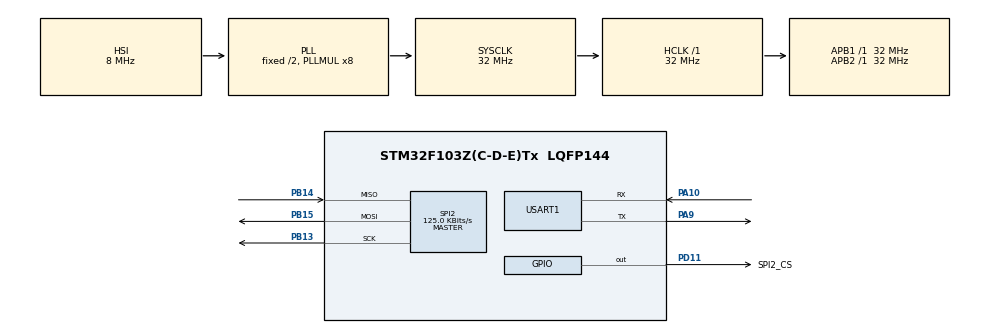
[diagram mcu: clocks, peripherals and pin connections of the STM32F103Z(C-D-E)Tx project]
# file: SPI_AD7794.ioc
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Mcu.Family=STM32F1
Mcu.Name=STM32F103Z(C-D-E)Tx
Mcu.Package=LQFP144
NVIC.PriorityGroup=NVIC_PRIORITYGROUP_4
OSC_IN.Mode=HSE-External-Oscillator
OSC_IN.Signal=RCC_OSC_IN
OSC_OUT.Mode=HSE-External-Oscillator
OSC_OUT.Signal=RCC_OSC_OUT
PA10.Mode=Asynchronous
PA10.Signal=USART1_RX
PA13.Mode=Serial_Wire
PA13.Signal=SYS_JTMS-SWDIO
PA14.Mode=Serial_Wire
PA14.Signal=SYS_JTCK-SWCLK
PA9.Mode=Asynchronous
PA9.Signal=USART1_TX
PB13.Mode=Full_Duplex_Master
PB13.Signal=SPI2_SCK
PB14.Mode=Full_Duplex_Master
PB14.Signal=SPI2_MISO
PB15.Mode=Full_Duplex_Master
PB15.Signal=SPI2_MOSI
PD11.GPIO_Label=SPI2_CS
PD11.GPIO_PuPd=GPIO_PULLUP
PD11.GPIO_Speed=GPIO_SPEED_FREQ_HIGH
PD11.PinState=GPIO_PIN_SET
PD11.Signal=GPIO_Output
ProjectManager.HeapSize=0x200
ProjectManager.StackSize=0x400
ProjectManager.TargetToolchain=MDK-ARM V5.32
RCC.AHBFreq_Value=32000000
RCC.APB1Freq_Value=32000000
RCC.APB1TimFreq_Value=32000000
RCC.APB2Freq_Value=32000000
RCC.APB2TimFreq_Value=32000000
RCC.HCLKFreq_Value=32000000
RCC.PLLMUL=RCC_PLL_MUL8
RCC.SYSCLKFreq_VALUE=32000000
RCC.SYSCLKSource=RCC_SYSCLKSOURCE_PLLCLK
RCC.USBFreq_Value=32000000
SPI2.BaudRatePrescaler=SPI_BAUDRATEPRESCALER_256
SPI2.CLKPhase=SPI_PHASE_2EDGE
SPI2.CLKPolarity=SPI_POLARITY_HIGH
SPI2.CalculateBaudRate=125.0 KBits/s
SPI2.Direction=SPI_DIRECTION_2LINES
SPI2.Mode=SPI_MODE_MASTER
SPI2.VirtualType=VM_MASTER
TIM5.Prescaler=71
USART1.VirtualMode=VM_ASYNC
VP_TIM5_VS_ClockSourceINT.Mode=Internal
board=custom

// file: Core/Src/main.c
/* USER CODE BEGIN Header */
/**
  ******************************************************************************
  * @file           : main.c
  * @brief          : Main program body
  ******************************************************************************
  * @attention
  *
  * Copyright (c) 2022 STMicroelectronics.
  * All rights reserved.
  *
  * This software is licensed under terms that can be found in the LICENSE file
  * in the root directory of this software component.
  * If no LICENSE file comes with this software, it is provided AS-IS.
  *
  ******************************************************************************
  */
/* USER CODE END Header */
#include "main.h"
#include "spi.h"
#include "tim.h"
#include "usart.h"
#include "gpio.h"

/* USER CODE BEGIN Includes */
#include "ALGORITHM.h"
#include "AD7794.h"
#include "stdio.h"
/* USER CODE END Includes */

/* USER CODE BEGIN PV */
uint32_t Code_AD7794;
float Resistance;
float Temp = 0.0f;
/* USER CODE END PV */

void SystemClock_Config(void);

int main(void)
{

  /* MCU Configuration--------------------------------------------------------*/

  /* Reset of all peripherals, Initializes the Flash interface and the Systick. */
  HAL_Init();

  /* Configure the system clock */
  SystemClock_Config();

  /* Initialize all configured peripherals */
  MX_GPIO_Init();
  MX_USART1_UART_Init();
  MX_TIM5_Init();
  MX_SPI2_Init();
  /* USER CODE BEGIN 2 */
	AD7794_Init();				//AD7794初始化
  /* USER CODE END 2 */

  /* Infinite loop */
  while (1)
  {

    /* USER CODE BEGIN 3 */

	Code_AD7794 = AD7794_Code_To_Res();
	Resistance =  0.001 * Code_AD7794;
	printf("RES=%.3f  \r\n", Resistance);
	Temp = resi_temp_calc(Resistance);
	printf("temp=%.1f C\r\n", Temp);
	HAL_Delay(10000);
  }
  /* USER CODE END 3 */
}

void SystemClock_Config(void)
{
  RCC_OscInitTypeDef RCC_OscInitStruct = {0};
  RCC_ClkInitTypeDef RCC_ClkInitStruct = {0};

  /** Initializes the RCC Oscillators according to the specified parameters
  * in the RCC_OscInitTypeDef structure.
  */
  RCC_OscInitStruct.OscillatorType = RCC_OSCILLATORTYPE_HSI;
  RCC_OscInitStruct.HSIState = RCC_HSI_ON;
  RCC_OscInitStruct.HSICalibrationValue = RCC_HSICALIBRATION_DEFAULT;
  RCC_OscInitStruct.PLL.PLLState = RCC_PLL_ON;
  RCC_OscInitStruct.PLL.PLLSource = RCC_PLLSOURCE_HSI_DIV2;
  RCC_OscInitStruct.PLL.PLLMUL = RCC_PLL_MUL8;
  if (HAL_RCC_OscConfig(&RCC_OscInitStruct) != HAL_OK)
  {
    Error_Handler();
  }

  /** Initializes the CPU, AHB and APB buses clocks
  */
  RCC_ClkInitStruct.ClockType = RCC_CLOCKTYPE_HCLK|RCC_CLOCKTYPE_SYSCLK
                              |RCC_CLOCKTYPE_PCLK1|RCC_CLOCKTYPE_PCLK2;
  RCC_ClkInitStruct.SYSCLKSource = RCC_SYSCLKSOURCE_PLLCLK;
  RCC_ClkInitStruct.AHBCLKDivider = RCC_SYSCLK_DIV1;
  RCC_ClkInitStruct.APB1CLKDivider = RCC_HCLK_DIV1;
  RCC_ClkInitStruct.APB2CLKDivider = RCC_HCLK_DIV1;

  if (HAL_RCC_ClockConfig(&RCC_ClkInitStruct, FLASH_LATENCY_1) != HAL_OK)
  {
    Error_Handler();
  }
}

void Error_Handler(void)
{
  __disable_irq();
  while (1)
  {
  }
}
